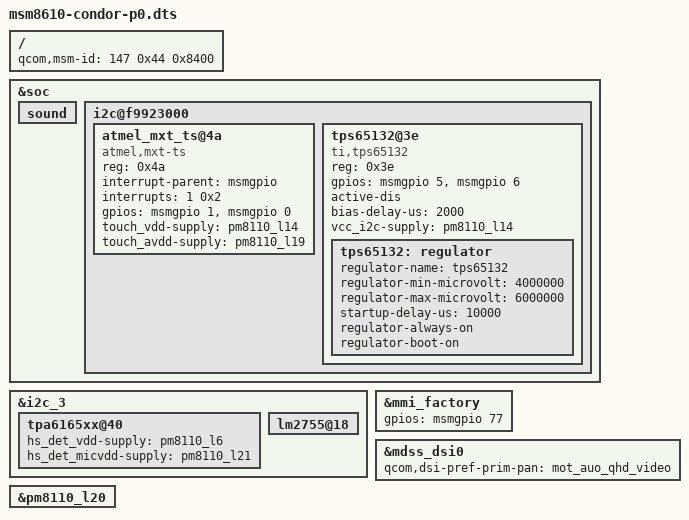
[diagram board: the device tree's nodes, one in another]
/* Copyright (c) 2013, The Linux Foundation. All rights reserved.
 *
 * This program is free software; you can redistribute it and/or modify
 * it under the terms of the GNU General Public License version 2 and
 * only version 2 as published by the Free Software Foundation.
 *
 * This program is distributed in the hope that it will be useful,
 * but WITHOUT ANY WARRANTY; without even the implied warranty of
 * MERCHANTABILITY or FITNESS FOR A PARTICULAR PURPOSE.  See the
 * GNU General Public License for more details.
 */

/dts-v1/;

/include/ "msm8610-moto-reserve.dtsi"
/include/ "msm8610-v1.dtsi"
/include/ "msm8610-moto-common.dtsi"
/include/ "dsi-v2-panel-mot-auo-qhd-video.dtsi"

/ {
	qcom,msm-id = <147 0x44 0x8400>;
};

&soc {
	/delete-node/ fan5646_vreg;
	/delete-node/ fan5646;

	sound {
		/delete-property/ qcom,ext-spk-amp-gpio;
		/delete-property/ boost-supply;
	};

	i2c@f9923000{
		/delete-node/ synaptics_dsx_i2c@20;

		atmel_mxt_ts@4a {
			compatible = "atmel,mxt-ts";
			reg = <0x4a>;
			interrupt-parent = <&msmgpio>;
			interrupts = <1 0x2>;
			gpios = <&msmgpio 1 0x0>, /* IRQ */
				<&msmgpio 0 0x0>; /* RESET */
			touch_vdd-supply = <&pm8110_l14>;
			touch_avdd-supply = <&pm8110_l19>;
		};

		tps65132@3e {
			compatible = "ti,tps65132";
			reg = <0x3e>;
			gpios = <&msmgpio 5 0x0>, <&msmgpio 6 0x0>;
			active-dis;
			bias-delay-us = <2000>;
			vcc_i2c-supply = <&pm8110_l14>;
			tps65132: regulator {
				regulator-name = "tps65132";
				regulator-min-microvolt = <4000000>;
				regulator-max-microvolt = <6000000>;
				startup-delay-us = <10000>;
				regulator-always-on;
				regulator-boot-on;
			};
		};
	};


	/delete-node/ vsp_disp_vreg;
};

&i2c_3 {
	tpa6165xx@40 {
		hs_det_vdd-supply = <&pm8110_l6>;
		hs_det_micvdd-supply = <&pm8110_l21>;
	};

	lm2755@18 {
		status = "ok";
	};
};

/* Support Gipper factory IC */
&mmi_factory {
	gpios = <&msmgpio 77 0x2>; /* GPIOF_DIR_OUT | GPIOF_INIT_HIGH */
};

&mdss_dsi0 {
	qcom,dsi-pref-prim-pan = <&mot_auo_qhd_video>;
};

&pm8110_l20 {
	/delete-property/ regulator-always-on;
};
